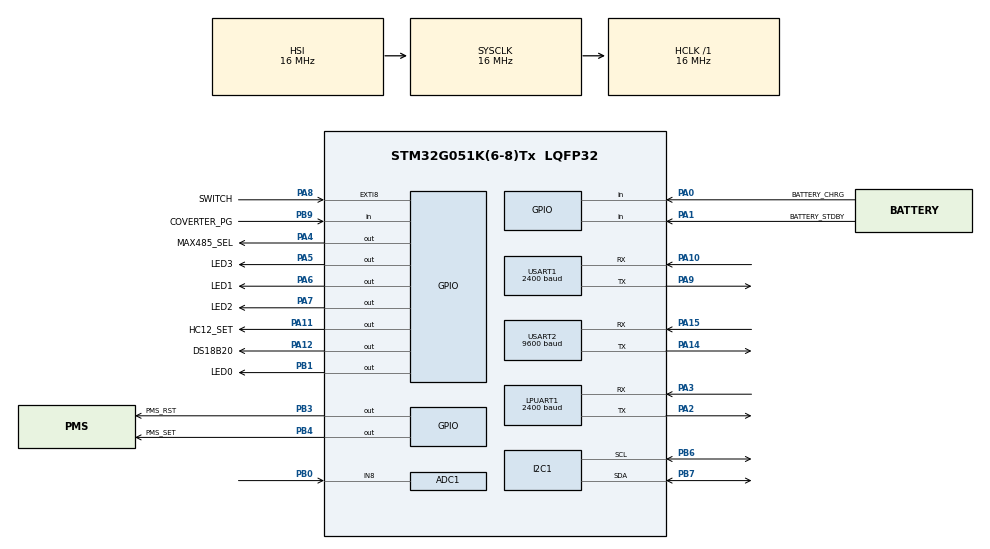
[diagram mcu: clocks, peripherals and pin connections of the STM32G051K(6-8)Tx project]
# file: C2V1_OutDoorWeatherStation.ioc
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ADC1.Channel-0\#ChannelRegularConversion=ADC_CHANNEL_8
ADC1.NbrOfConversionFlag=1
ADC1.Rank-0\#ChannelRegularConversion=1
ADC1.SamplingTime-0\#ChannelRegularConversion=ADC_SAMPLINGTIME_COMMON_1
ADC1.SelectedChannel=ADC_CHANNEL_8
ADC1.master=1
Dma.LPUART1_RX.1.Direction=DMA_PERIPH_TO_MEMORY
Dma.LPUART1_RX.1.EventEnable=DISABLE
Dma.LPUART1_RX.1.Instance=DMA1_Channel2
Dma.LPUART1_RX.1.MemDataAlignment=DMA_MDATAALIGN_BYTE
Dma.LPUART1_RX.1.MemInc=DMA_MINC_ENABLE
Dma.LPUART1_RX.1.Mode=DMA_NORMAL
Dma.LPUART1_RX.1.PeriphDataAlignment=DMA_PDATAALIGN_BYTE
Dma.LPUART1_RX.1.PeriphInc=DMA_PINC_DISABLE
Dma.LPUART1_RX.1.Polarity=HAL_DMAMUX_REQ_GEN_RISING
Dma.LPUART1_RX.1.Priority=DMA_PRIORITY_VERY_HIGH
Dma.LPUART1_RX.1.RequestNumber=1
Dma.LPUART1_RX.1.SignalID=NONE
Dma.LPUART1_RX.1.SyncEnable=DISABLE
Dma.LPUART1_RX.1.SyncPolarity=HAL_DMAMUX_SYNC_NO_EVENT
Dma.LPUART1_RX.1.SyncRequestNumber=1
Dma.LPUART1_RX.1.SyncSignalID=NONE
Dma.Request0=USART1_RX
Dma.Request1=LPUART1_RX
Dma.Request2=USART2_RX
Dma.USART1_RX.0.Direction=DMA_PERIPH_TO_MEMORY
Dma.USART1_RX.0.EventEnable=DISABLE
Dma.USART1_RX.0.Instance=DMA1_Channel1
Dma.USART1_RX.0.MemDataAlignment=DMA_MDATAALIGN_BYTE
Dma.USART1_RX.0.MemInc=DMA_MINC_ENABLE
Dma.USART1_RX.0.Mode=DMA_NORMAL
Dma.USART1_RX.0.PeriphDataAlignment=DMA_PDATAALIGN_BYTE
Dma.USART1_RX.0.PeriphInc=DMA_PINC_DISABLE
Dma.USART1_RX.0.Polarity=HAL_DMAMUX_REQ_GEN_RISING
Dma.USART1_RX.0.Priority=DMA_PRIORITY_VERY_HIGH
Dma.USART1_RX.0.RequestNumber=1
Dma.USART1_RX.0.SignalID=NONE
Dma.USART1_RX.0.SyncEnable=DISABLE
Dma.USART1_RX.0.SyncPolarity=HAL_DMAMUX_SYNC_NO_EVENT
Dma.USART1_RX.0.SyncRequestNumber=1
Dma.USART1_RX.0.SyncSignalID=NONE
Dma.USART2_RX.2.Direction=DMA_PERIPH_TO_MEMORY
Dma.USART2_RX.2.EventEnable=DISABLE
Dma.USART2_RX.2.Instance=DMA1_Channel3
Dma.USART2_RX.2.MemDataAlignment=DMA_MDATAALIGN_BYTE
Dma.USART2_RX.2.MemInc=DMA_MINC_ENABLE
Dma.USART2_RX.2.Mode=DMA_NORMAL
Dma.USART2_RX.2.PeriphDataAlignment=DMA_PDATAALIGN_BYTE
Dma.USART2_RX.2.PeriphInc=DMA_PINC_DISABLE
Dma.USART2_RX.2.Polarity=HAL_DMAMUX_REQ_GEN_RISING
Dma.USART2_RX.2.Priority=DMA_PRIORITY_LOW
Dma.USART2_RX.2.RequestNumber=1
Dma.USART2_RX.2.SignalID=NONE
Dma.USART2_RX.2.SyncEnable=DISABLE
Dma.USART2_RX.2.SyncPolarity=HAL_DMAMUX_SYNC_NO_EVENT
Dma.USART2_RX.2.SyncRequestNumber=1
Dma.USART2_RX.2.SyncSignalID=NONE
LPUART1.BaudRate=2400
LPUART1.ClockPrescaler=UART_PRESCALER_DIV16
LPUART1.DMADisableonRxErrorParam=UART_ADVFEATURE_DMA_DISABLEONRXERROR
LPUART1.OverrunDisableParam=UART_ADVFEATURE_OVERRUN_DISABLE
LPUART1.WordLength=UART_WORDLENGTH_8B
Mcu.Family=STM32G0
Mcu.Name=STM32G051K(6-8)Tx
Mcu.Package=LQFP32
NVIC.DMA1_Channel1_IRQn=true\:0\:0\:false\:true\:true\:1\:false\:true\:true
NVIC.DMA1_Channel2_3_IRQn=true\:0\:0\:false\:true\:true\:4\:false\:true\:true
NVIC.EXTI4_15_IRQn=true\:0\:0\:false\:true\:true\:5\:true\:true\:true
NVIC.LPUART1_IRQn=true\:0\:0\:false\:true\:true\:3\:true\:true\:true
NVIC.RTC_TAMP_IRQn=true\:0\:0\:false\:true\:true\:7\:true\:true\:true
NVIC.TIM17_IRQn=true\:0\:0\:false\:true\:true\:6\:true\:true\:true
NVIC.USART1_IRQn=true\:0\:0\:false\:true\:true\:2\:true\:true\:true
NVIC.USART2_IRQn=true\:0\:0\:false\:false\:true\:true\:true\:true
PA0.GPIO_Label=BATTERY_CHRG
PA0.Signal=GPIO_Input
PA1.GPIO_Label=BATTERY_STDBY
PA1.Signal=GPIO_Input
PA10.Mode=Asynchronous
PA10.Signal=USART1_RX
PA11\ [PA9].GPIO_Label=HC12_SET
PA11\ [PA9].PinState=GPIO_PIN_SET
PA11\ [PA9].Signal=GPIO_Output
PA12\ [PA10].GPIO_Label=DS18B20
PA12\ [PA10].GPIO_Speed=GPIO_SPEED_FREQ_VERY_HIGH
PA12\ [PA10].Signal=GPIO_Output
PA14-BOOT0.Mode=Asynchronous
PA14-BOOT0.Signal=USART2_TX
PA15.Mode=Asynchronous
PA15.Signal=USART2_RX
PA2.Mode=Asynchronous
PA2.Signal=LPUART1_TX
PA3.Mode=Asynchronous
PA3.Signal=LPUART1_RX
PA4.GPIO_Label=MAX485_SEL
PA4.Signal=GPIO_Output
PA5.GPIO_Label=LED3
PA5.Signal=GPIO_Output
PA6.GPIO_Label=LED1
PA6.Signal=GPIO_Output
PA7.GPIO_Label=LED2
PA7.Signal=GPIO_Output
PA8.GPIO_Label=SWITCH
PA8.GPIO_ModeDefaultEXTI=GPIO_MODE_IT_FALLING
PA8.Signal=GPXTI8
PA9.Mode=Asynchronous
PA9.Signal=USART1_TX
PB0.Mode=IN8
PB0.Signal=ADC1_IN8
PB1.GPIO_Label=LED0
PB1.Signal=GPIO_Output
PB3.GPIO_Label=PMS_RST
PB3.PinState=GPIO_PIN_SET
PB3.Signal=GPIO_Output
PB4.GPIO_Label=PMS_SET
PB4.Signal=GPIO_Output
PB6.GPIO_Speed=GPIO_SPEED_FREQ_VERY_HIGH
PB6.Mode=I2C
PB6.Signal=I2C1_SCL
PB7.GPIO_Speed=GPIO_SPEED_FREQ_VERY_HIGH
PB7.Mode=I2C
PB7.Signal=I2C1_SDA
PB9.GPIO_Label=COVERTER_PG
PB9.Signal=GPIO_Input
ProjectManager.HeapSize=0x400
ProjectManager.StackSize=0x8000
ProjectManager.TargetToolchain=STM32CubeIDE
RCC.ADCFreq_Value=16000000
RCC.AHBFreq_Value=16000000
RCC.CortexFreq_Value=16000000
RCC.EXTERNAL_CLOCK_VALUE=48000
RCC.HCLKFreq_Value=16000000
RCC.HSE_VALUE=8000000
RCC.HSI_VALUE=16000000
RCC.LPUART1CLockSelection=RCC_LPUART1CLKSOURCE_HSI
RCC.LSE_VALUE=32768
RCC.SYSCLKFreq_VALUE=16000000
RCC.USART1CLockSelection=RCC_USART1CLKSOURCE_HSI
RCC.VCOOutputFreq_Value=128000000
RTC.WakeUpClock-WakeUp=RTC_WAKEUPCLOCK_CK_SPRE_16BITS
TIM17.AutoReloadPreload=TIM_AUTORELOAD_PRELOAD_DISABLE
TIM17.Period=99
TIM17.Prescaler=63999
USART1.BaudRate=2400
USART1.VirtualMode-Asynchronous=VM_ASYNC
USART2.BaudRate=9600
USART2.OverrunDisableParam=ADVFEATURE_OVERRUN_DISABLE
USART2.SwapParam=ADVFEATURE_SWAP_ENABLE
USART2.VirtualMode-Asynchronous=VM_ASYNC
VP_RTC_VS_RTC_Activate.Mode=RTC_Enabled
VP_RTC_VS_RTC_WakeUp_intern.Mode=WakeUp
VP_TIM17_VS_ClockSourceINT.Mode=Enable_Timer
board=custom

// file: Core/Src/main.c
/* USER CODE BEGIN Header */
/**
 ******************************************************************************
 * @file           : main.c
 * @brief          : Main program body
 ******************************************************************************
 * @attention
 *
 * Copyright (c) 2022 STMicroelectronics.
 * All rights reserved.
 *
 * This software is licensed under terms that can be found in the LICENSE file
 * in the root directory of this software component.
 * If no LICENSE file comes with this software, it is provided AS-IS.
 *
 ******************************************************************************
 */
/* USER CODE END Header */
#include "main.h"
#include "adc.h"
#include "dma.h"
#include "i2c.h"
#include "usart.h"
#include "rtc.h"
#include "tim.h"
#include "gpio.h"

/* USER CODE BEGIN Includes */
#include "SM.h"
/* USER CODE END Includes */

void SystemClock_Config(void);
static void MX_NVIC_Init(void);

int main(void)
{

  /* MCU Configuration--------------------------------------------------------*/

  /* Reset of all peripherals, Initializes the Flash interface and the Systick. */
  HAL_Init();

  /* Configure the system clock */
  SystemClock_Config();

  /* Initialize all configured peripherals */
  MX_GPIO_Init();
  MX_DMA_Init();
  MX_ADC1_Init();
  MX_I2C1_Init();
  MX_LPUART1_UART_Init();
  MX_USART1_UART_Init();
  MX_TIM17_Init();
  MX_RTC_Init();
  MX_USART2_UART_Init();

  /* Initialize interrupts */
  MX_NVIC_Init();
  /* USER CODE BEGIN 2 */
   //HAL_Delay(10000);
  /* USER CODE END 2 */

  /* Infinite loop */
  /* USER CODE BEGIN WHILE */
   while(1)
   {
      SM_Handle();
    /* USER CODE END WHILE */

   }
}

void SystemClock_Config(void)
{
  RCC_OscInitTypeDef RCC_OscInitStruct = {0};
  RCC_ClkInitTypeDef RCC_ClkInitStruct = {0};

  /** Configure the main internal regulator output voltage
  */
  HAL_PWREx_ControlVoltageScaling(PWR_REGULATOR_VOLTAGE_SCALE1);

  /** Initializes the RCC Oscillators according to the specified parameters
  * in the RCC_OscInitTypeDef structure.
  */
  RCC_OscInitStruct.OscillatorType = RCC_OSCILLATORTYPE_HSI|RCC_OSCILLATORTYPE_LSI;
  RCC_OscInitStruct.HSIState = RCC_HSI_ON;
  RCC_OscInitStruct.HSIDiv = RCC_HSI_DIV1;
  RCC_OscInitStruct.HSICalibrationValue = RCC_HSICALIBRATION_DEFAULT;
  RCC_OscInitStruct.LSIState = RCC_LSI_ON;
  RCC_OscInitStruct.PLL.PLLState = RCC_PLL_NONE;
  if (HAL_RCC_OscConfig(&RCC_OscInitStruct) != HAL_OK)
  {
    Error_Handler();
  }

  /** Initializes the CPU, AHB and APB buses clocks
  */
  RCC_ClkInitStruct.ClockType = RCC_CLOCKTYPE_HCLK|RCC_CLOCKTYPE_SYSCLK
                              |RCC_CLOCKTYPE_PCLK1;
  RCC_ClkInitStruct.SYSCLKSource = RCC_SYSCLKSOURCE_HSI;
  RCC_ClkInitStruct.AHBCLKDivider = RCC_SYSCLK_DIV1;
  RCC_ClkInitStruct.APB1CLKDivider = RCC_HCLK_DIV1;

  if (HAL_RCC_ClockConfig(&RCC_ClkInitStruct, FLASH_LATENCY_0) != HAL_OK)
  {
    Error_Handler();
  }
}

/**
  * @brief NVIC Configuration.
  * @retval None
  */
static void MX_NVIC_Init(void)
{
  /* DMA1_Channel1_IRQn interrupt configuration */
  HAL_NVIC_SetPriority(DMA1_Channel1_IRQn, 0, 0);
  HAL_NVIC_EnableIRQ(DMA1_Channel1_IRQn);
  /* USART1_IRQn interrupt configuration */
  HAL_NVIC_SetPriority(USART1_IRQn, 0, 0);
  HAL_NVIC_EnableIRQ(USART1_IRQn);
  /* LPUART1_IRQn interrupt configuration */
  HAL_NVIC_SetPriority(LPUART1_IRQn, 0, 0);
  HAL_NVIC_EnableIRQ(LPUART1_IRQn);
  /* DMA1_Channel2_3_IRQn interrupt configuration */
  HAL_NVIC_SetPriority(DMA1_Channel2_3_IRQn, 0, 0);
  HAL_NVIC_EnableIRQ(DMA1_Channel2_3_IRQn);
  /* EXTI4_15_IRQn interrupt configuration */
  HAL_NVIC_SetPriority(EXTI4_15_IRQn, 0, 0);
  HAL_NVIC_EnableIRQ(EXTI4_15_IRQn);
  /* TIM17_IRQn interrupt configuration */
  HAL_NVIC_SetPriority(TIM17_IRQn, 0, 0);
  HAL_NVIC_EnableIRQ(TIM17_IRQn);
  /* RTC_TAMP_IRQn interrupt configuration */
  HAL_NVIC_SetPriority(RTC_TAMP_IRQn, 0, 0);
  HAL_NVIC_EnableIRQ(RTC_TAMP_IRQn);
}

void Error_Handler(void)
{
   __disable_irq();
   while(1)
   {
   }
}
